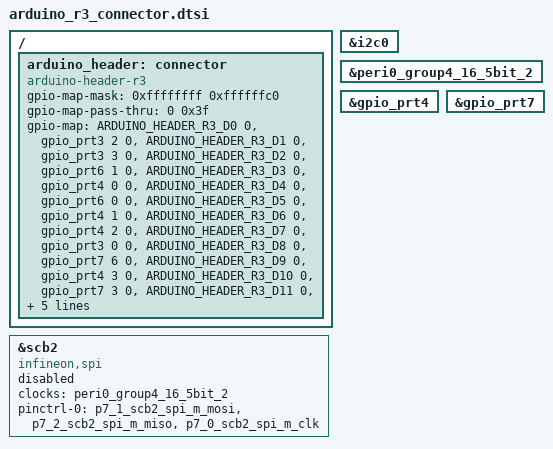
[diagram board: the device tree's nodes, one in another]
/*
 * SPDX-FileCopyrightText: Copyright (c) 2026 Infineon Technologies AG,
 * SPDX-FileCopyrightText: or an affiliate of Infineon Technologies AG. All rights reserved.
 *
 * SPDX-License-Identifier: Apache-2.0
 */

/*
 * Arduino UNO R3 connector on J1 to J4, per kit user guide 002-39385 Rev. *B,
 * Table 3.
 *
 * A0 to A5 on J2 are the dedicated analog inputs AN_A0 to AN_A5, which are
 * not GPIO pins, so they are absent from the map.
 *
 * D2 and D4 are also the console UART's RTS and CTS (P6.1, P6.0), and D8 is
 * shared with the CAN FD transceiver's STB pin (P7.6).
 */

#include <zephyr/dt-bindings/gpio/arduino-header-r3.h>

/ {
	arduino_header: connector {
		compatible = "arduino-header-r3";
		#gpio-cells = <2>;
		gpio-map-mask = <0xffffffff 0xffffffc0>;
		gpio-map-pass-thru = <0 0x3f>;
		gpio-map = <ARDUINO_HEADER_R3_D0 0 &gpio_prt3 2 0>,
			   <ARDUINO_HEADER_R3_D1 0 &gpio_prt3 3 0>,
			   <ARDUINO_HEADER_R3_D2 0 &gpio_prt6 1 0>,
			   <ARDUINO_HEADER_R3_D3 0 &gpio_prt4 0 0>,
			   <ARDUINO_HEADER_R3_D4 0 &gpio_prt6 0 0>,
			   <ARDUINO_HEADER_R3_D5 0 &gpio_prt4 1 0>,
			   <ARDUINO_HEADER_R3_D6 0 &gpio_prt4 2 0>,
			   <ARDUINO_HEADER_R3_D7 0 &gpio_prt3 0 0>,
			   <ARDUINO_HEADER_R3_D8 0 &gpio_prt7 6 0>,
			   <ARDUINO_HEADER_R3_D9 0 &gpio_prt4 3 0>,
			   <ARDUINO_HEADER_R3_D10 0 &gpio_prt7 3 0>,
			   <ARDUINO_HEADER_R3_D11 0 &gpio_prt7 1 0>,
			   <ARDUINO_HEADER_R3_D12 0 &gpio_prt7 2 0>,
			   <ARDUINO_HEADER_R3_D13 0 &gpio_prt7 0 0>,
			   <ARDUINO_HEADER_R3_D14 0 &gpio_prt9 2 0>,
			   <ARDUINO_HEADER_R3_D15 0 &gpio_prt9 0 0>;
	};
};

arduino_i2c: &i2c0 {};

/*
 * SCB2 on D11 (MOSI), D12 (MISO) and D13 (SCK).  Left disabled; a shield
 * enables it and supplies the chip select, normally on D10.
 */
arduino_spi: &scb2 {
	compatible = "infineon,spi";
	#address-cells = <1>;
	#size-cells = <0>;

	clocks = <&peri0_group4_16_5bit_2>;

	pinctrl-0 = <&p7_1_scb2_spi_m_mosi &p7_2_scb2_spi_m_miso &p7_0_scb2_spi_m_clk>;
	pinctrl-names = "default";
	status = "disabled";
};

&peri0_group4_16_5bit_2 {
	status = "okay";
};

/* D3, D5, D6 and D9 are on port 4; D8 and D10 to D13 on port 7. */
&gpio_prt4 {
	status = "okay";
};

&gpio_prt7 {
	status = "okay";
};
